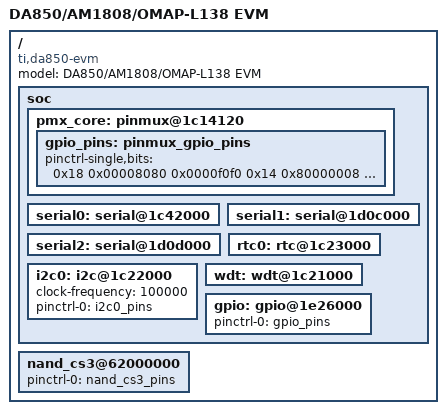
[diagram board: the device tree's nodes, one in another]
/*
 * Device Tree for DA850 EVM board
 *
 * Copyright (C) 2012 Texas Instruments Incorporated - http://www.ti.com/
 *
 * This program is free software; you can redistribute  it and/or modify it
 * under  the terms of  the GNU General  Public License as published by the
 * Free Software Foundation, version 2.
 */
/dts-v1/;
/include/ "da850.dtsi"

/ {
	compatible = "ti,da850-evm", "ti,da850";
	model = "DA850/AM1808/OMAP-L138 EVM";

	soc {
		pmx_core: pinmux@1c14120 {
			status = "okay";
			gpio_pins: pinmux_gpio_pins {
				pinctrl-single,bits = <
					/* GPIO2_4 GPIO2_6 */
					0x18 0x00008080 0x0000f0f0
					/* GPIO2_8 GPIO2_15 */
					0x14 0x80000008 0xf000000f
					/* GPIO3_12 GPIO3_13 */
					0x1C 0x00008800 0x0000ff00
					/* GPIO4_0 GPIO4_1 */
					0x28 0x88000000 0xff000000
					/* GPIO6_9 GPIO6_10 GPIO6_13 */
					0x34 0x08800800 0x0ff00f00
				>;
			};
		};
		serial0: serial@1c42000 {
			status = "okay";
		};
		serial1: serial@1d0c000 {
			status = "okay";
		};
		serial2: serial@1d0d000 {
			status = "okay";
		};
		rtc0: rtc@1c23000 {
			status = "okay";
		};
		i2c0: i2c@1c22000 {
			status = "okay";
			clock-frequency = <100000>;
			pinctrl-names = "default";
			pinctrl-0 = <&i2c0_pins>;
		};
		wdt: wdt@1c21000 {
			status = "okay";
		};
		gpio: gpio@1e26000 {
			status = "okay";
			pinctrl-names = "default";
			pinctrl-0 = <&gpio_pins>;
		};
	};
	nand_cs3@62000000 {
		status = "okay";
		pinctrl-names = "default";
		pinctrl-0 = <&nand_cs3_pins>;
	};
};
